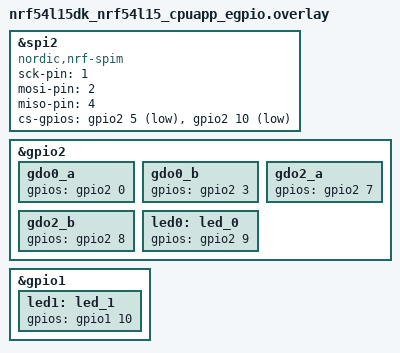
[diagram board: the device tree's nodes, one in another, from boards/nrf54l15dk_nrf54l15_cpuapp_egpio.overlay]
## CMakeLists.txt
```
cmake_minimum_required(VERSION 3.20.0)
find_package(Zephyr REQUIRED HINTS $ENV{ZEPHYR_BASE})

project(433MHz_Dual_Module)

target_sources(app PRIVATE src/main.c)
target_include_directories(app PRIVATE ${CMAKE_CURRENT_SOURCE_DIR}/include)
```

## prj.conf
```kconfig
# prj.conf

# 基础功能
CONFIG_GPIO=y
CONFIG_SPI=y

# 日志功能
CONFIG_LOG=y
CONFIG_LOG_DEFAULT_LEVEL=3

# 如有需要串口打印
CONFIG_CONSOLE=y
CONFIG_UART_CONSOLE=y

# 如果您用到了多线程/多任务，可以启用
# CONFIG_THREAD_NAME=y

# 如果您需要低功耗、蓝牙等功能，再添加其他 Kconfig 配置
```

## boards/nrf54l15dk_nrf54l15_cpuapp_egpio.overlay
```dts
/* cc1101.overlay */
&spi2 {
    compatible = "nordic,nrf-spim";
    status = "okay";
    sck-pin = <1>;      // P2.01 (SPI 时钟)
    mosi-pin = <2>;     // P2.02 (SPI 主输出)
    miso-pin = <4>;     // P2.04 (SPI 主输入)
    cs-gpios = <&gpio2 5 GPIO_ACTIVE_LOW>,  // P2.05 (CSN，模块 A)
              <&gpio2 10 GPIO_ACTIVE_LOW>; // P2.10 (CSN，模块 B)
};

&gpio2 {
    gdo0_a: gdo0_a {
        gpios = <&gpio2 0 GPIO_ACTIVE_HIGH>; // P2.00 (GDO0，模块 A)
    };
    gdo0_b: gdo0_b {
        gpios = <&gpio2 3 GPIO_ACTIVE_HIGH>; // P2.03 (GDO0，模块 B)
    };
    gdo2_a: gdo2_a {
        gpios = <&gpio2 7 GPIO_ACTIVE_HIGH>; // P2.07 (GDO2，模块 A)
    };
    gdo2_b: gdo2_b {
        gpios = <&gpio2 8 GPIO_ACTIVE_HIGH>; // P2.08 (GDO2，模块 B)
    };
};

&gpio2 {
    led0: led_0 {
        gpios = <&gpio2 9 GPIO_ACTIVE_HIGH>; // P2.09 (LED0，模块 A)
    };
};

&gpio1 {
    led1: led_1 {
        gpios = <&gpio1 10 GPIO_ACTIVE_HIGH>; // P1.10 (LED1，模块 B)
    };
};
```

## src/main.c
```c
#include <zephyr/kernel.h>
#include <zephyr/device.h>
#include <zephyr/drivers/gpio.h>
#include <zephyr/drivers/spi.h>
#include <zephyr/logging/log.h>
#include <zephyr/devicetree.h>
#include "cc1101.h"

LOG_MODULE_REGISTER(main);

static struct cc1101_config module_a_config = {
    .spi = DEVICE_DT_GET(DT_NODELABEL(spi2)),
    .cs_ctrl = {
        .gpio_dev = DEVICE_DT_GET(DT_NODELABEL(gpio2)),
        .gpio_pin = 5, // CSN for Module A
        .delay = 0,
    },
    .gdo0 = GPIO_DT_SPEC_GET(DT_NODELABEL(gdo0_a), gpios),
    .gdo2 = GPIO_DT_SPEC_GET(DT_NODELABEL(gdo2_a), gpios),
};

static struct cc1101_config module_b_config = {
    .spi = DEVICE_DT_GET(DT_NODELABEL(spi2)),
    .cs_ctrl = {
        .gpio_dev = DEVICE_DT_GET(DT_NODELABEL(gpio2)),
        .gpio_pin = 10, // CSN for Module B
        .delay = 0,
    },
    .gdo0 = GPIO_DT_SPEC_GET(DT_NODELABEL(gdo0_b), gpios),
    .gdo2 = GPIO_DT_SPEC_GET(DT_NODELABEL(gdo2_b), gpios),
};

static const struct gpio_dt_spec led0 = GPIO_DT_SPEC_GET(DT_NODELABEL(led0), gpios); // P2.09
static const struct gpio_dt_spec led1 = GPIO_DT_SPEC_GET(DT_NODELABEL(led1), gpios); // P1.10

void main(void) {
    uint8_t status_a, status_b;

    // 初始化 LED
    gpio_pin_configure(led0.port, led0.pin, GPIO_OUTPUT_ACTIVE);
    gpio_pin_configure(led1.port, led1.pin, GPIO_OUTPUT_ACTIVE);

    gpio_pin_set(led0.port, led0.pin, 0);
    gpio_pin_set(led1.port, led1.pin, 0);

    // 初始化 CC1101 模块
    if (cc1101_init(&module_a_config) != 0) {
        LOG_ERR("模块 A 初始化失败");
        return;
    }
    if (cc1101_init(&module_b_config) != 0) {
        LOG_ERR("模块 B 初始化失败");
        return;
    }

    // 测试模块 A
    if (cc1101_test_status(&module_a_config, &status_a) == 0) {
        LOG_INF("模块 A 状态: 0x%02X", status_a);
        gpio_pin_set(led0.port, led0.pin, 1); // 如果模块 A 工作，点亮 LED0
    } else {
        LOG_ERR("无法获取模块 A 的状态");
    }

    // 测试模块 B
    if (cc1101_test_status(&module_b_config, &status_b) == 0) {
        LOG_INF("模块 B 状态: 0x%02X", status_b);
        gpio_pin_set(led1.port, led1.pin, 1); // 如果模块 B 工作，点亮 LED1
    } else {
        LOG_ERR("无法获取模块 B 的状态");
    }
}
```

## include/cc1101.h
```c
/* cc1101_driver.h */
#ifndef CC1101_DRIVER_H
#define CC1101_DRIVER_H

#include <zephyr/kernel.h>
#include <zephyr/device.h>
#include <zephyr/drivers/spi.h>
#include <zephyr/drivers/gpio.h>


#define CC1101_SRES       0x30
#define CC1101_PARTNUM    0x30
#define CC1101_VERSION    0x31

struct cc1101_config {
    const struct device *spi;
    struct spi_cs_control cs_ctrl;
    const struct gpio_dt_spec gdo0;
    const struct gpio_dt_spec gdo2;
};

int cc1101_init(const struct cc1101_config *config);
int cc1101_test_status(const struct cc1101_config *config, uint8_t *status);

#endif
```
